# THEJAS32 register map
Vendor: CDAC; Series: VEGA; File version: 1.0
CDAC VEGA THEJAS32 RISC-V SoC
CPU: other r0p0, little endian, no MPU, no FPU, 0 interrupt priority bits
Registers are 32-bit, read-write, reset 0x0 unless marked. A register's access mark holds for its fields unless they carry their own. Offsets are from the block's base; lines under a group give offsets from that group; [hi:lo] are bit positions; {n}, {i} and the like mark numbered series; 'fields as' and 'values as' point back to an identical list; <NAME> marks a mode.

## Memory map
0x10000100 UART0 size 0x100 — UART channel 0
0x10000200 UART1 size 0x100 — UART channel 1
0x10000300 UART2 size 0x100 — UART channel 2
0x10000600 SPI0 size 0x100 — SPI controller 0
0x10000700 SPI1 size 0x100 — SPI controller 1
0x10000800 I2C0 size 0x100 — I2C controller 0
0x10000900 I2C1 size 0x100 — I2C controller 1
0x10000A00 TIMER0 size 0x100 — Timer channel 0
0x10000A00 TIMER_GLOBAL size 0x100 — Timer global interrupt status registers
0x10000A14 TIMER1 size 0x100 — Timer channel 1
0x10000A28 TIMER2 size 0x100 — Timer channel 2
0x10001000 I2C2 size 0x100 — I2C controller 2 - bus for the board's onboard ADS1015 ADC
0x10001000 ADC size 0x100 — 4-channel ADC
0x10080000 GPIO0 size 0x50000 — GPIO bank 0 (pins 0-15)
0x10180000 GPIO1 size 0x50000 — GPIO bank 1 (pins 16-31)
0x10200100 SPI2 size 0x100 — SPI controller 2
0x10200200 SPI3 size 0x100 — SPI controller 3
{0x10400000+0x10*n} PWM{n} size 0x100 (n=0..7) — PWM channel {n}
0x10400080 PWM_GLOBAL size 0x100 — PWM global control
0x20010000 PLIC size 0x800 — Platform-Level Interrupt Controller

## Interrupts
0 UART0
1 UART1
2 UART2
3 SPI0
4 SPI1
5 I2C0
6 I2C1
7 TIMER0
8 TIMER1
9 TIMER2
10 GPIO0
{n+10} GPIO{n} (GPIO0) (n=1..12)

## UART0 — UART channel 0
Base 0x10000100
Same registers: UART1 0x10000200, UART2 0x10000300
0x00 RBR ro — Receiver Buffer Register
  [7:0] DATA — Received data byte
0x00 THR wo (alternate view of RBR) — Transmit Holding Register
  [7:0] DATA — Transmit data byte
0x00 DLL (alternate view of RBR) — Divisor Latch Low Register
  [7:0] DATA — Divisor latch low byte when LCR.DLAB=1
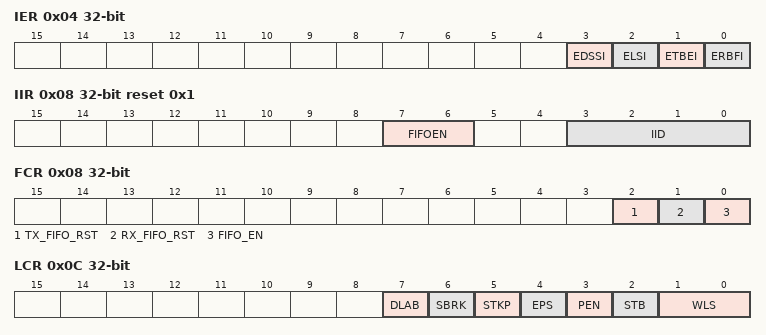
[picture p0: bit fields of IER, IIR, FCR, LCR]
0x04 IER — Interrupt Enable Register
  [3] EDSSI — Enable modem status interrupt
  [2] ELSI — Enable receiver line status interrupt
  [1] ETBEI — Enable transmitter holding register empty interrupt
  [0] ERBFI — Enable received data available interrupt
0x04 DLH (alternate view of IER) — Divisor Latch High Register
  [7:0] DATA — Divisor latch high byte when LCR.DLAB=1
0x08 IIR ro reset 0x1 — Interrupt Identification Register
  [7:6] FIFOEN — FIFO enable status
  [3:0] IID — Interrupt identification
0x08 FCR wo (alternate view of IIR) — FIFO Control Register
  [2] TX_FIFO_RST — Transmit FIFO reset
  [1] RX_FIFO_RST — Receive FIFO reset
  [0] FIFO_EN — FIFO enable
0x0C LCR — Line Control Register
  [7] DLAB — Divisor latch access bit
  [6] SBRK — Set break
  [5] STKP — Stick parity
  [4] EPS — Even parity select
  [3] PEN — Parity enable
  [2] STB — Number of stop bits
  [1:0] WLS — Word length select (0=5bit,1=6bit,2=7bit,3=8bit)
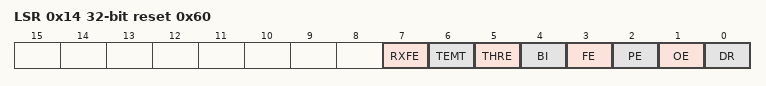
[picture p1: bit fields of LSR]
0x14 LSR ro reset 0x60 — Line Status Register
  [7] RXFE — Receiver FIFO error
  [6] TEMT — Transmitter empty
  [5] THRE — Transmitter holding register empty
  [4] BI — Break interrupt
  [3] FE — Framing error
  [2] PE — Parity error
  [1] OE — Overrun error
  [0] DR — Data ready

## SPI0 — SPI controller 0
Base 0x10000600
Same registers: SPI1 0x10000700, SPI2 0x10200100, SPI3 0x10200200
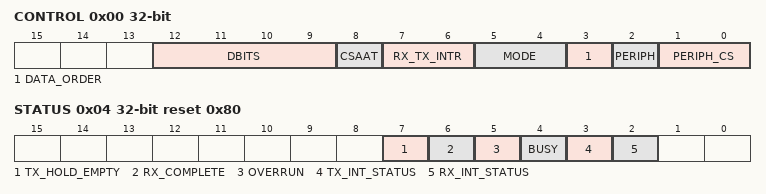
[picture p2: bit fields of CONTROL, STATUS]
0x00 CONTROL — SPI Control Register
  [12:9] DBITS — Data bits per transfer
  [8] CSAAT — Chip select active after transfer
  [7:6] RX_TX_INTR — RX/TX interrupt enable
  [5:4] MODE — SPI mode (clock polarity/phase)
  [3] DATA_ORDER — Data order (0=MSB first, 1=LSB first)
  [2] PERIPH — Peripheral type (0=fixed, 1=variable)
  [1:0] PERIPH_CS — Peripheral chip select
0x04 STATUS ro reset 0x80 — SPI Status Register
  [7] TX_HOLD_EMPTY — Transmit holding register empty
  [6] RX_COMPLETE — Receive complete
  [5] OVERRUN — Overrun error
  [4] BUSY — SPI busy
  [3] TX_INT_STATUS — TX interrupt status
  [2] RX_INT_STATUS — RX interrupt status
0x08 BAUDRATE reset 0x60 — SPI Baud Rate Divisor
0x0C TXDATA wo — SPI Transmit Data Register
  [15:0] DATA — Transmit data
0x10 RXDATA ro — SPI Receive Data Register
  [15:0] DATA — Received data

## I2C0 — I2C controller 0
Base 0x10000800
Same registers: I2C1 0x10000900, I2C2 0x10001000
0x00 CR 8-bit — Control Register
0x01 SR0 8-bit ro reset 0xD8 — Status Register 0
0x02 SR1 8-bit ro — Status Register 1
0x03 IER 8-bit — Interrupt Enable Register
0x04 TXFF 8-bit wo — Transmit FIFO
0x05 RXFF 8-bit ro — Receive FIFO
0x06 CHL 8-bit reset 0x7D — Clock Low Period
0x07 CHH 8-bit — Clock High Period
0x08 CHHL 8-bit reset 0x3E — Clock Low Period (extended)
0x09 CHHH 8-bit — Clock High Period (extended)
0x0A TXCLR 8-bit wo — TX Clear

## TIMER0 — Timer channel 0
Base 0x10000A00
Same registers: TIMER1 0x10000A14, TIMER2 0x10000A28
0x00 LOAD_COUNT — Timer load count value
0x04 CURRENT_VALUE ro — Timer current value
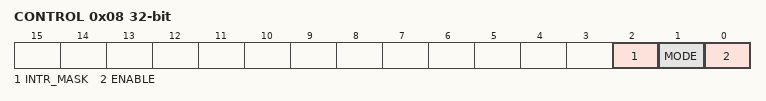
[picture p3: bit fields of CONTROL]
0x08 CONTROL — Timer control register
  [2] INTR_MASK — Interrupt mask (0=unmasked, 1=masked)
  [1] MODE — Timer mode (0=free-running, 1=user-defined)
  [0] ENABLE — Timer enable
0x0C EOI ro — Timer end-of-interrupt (read clears interrupt)
0x10 INTR_STATUS ro — Timer interrupt status

## TIMER_GLOBAL — Timer global interrupt status registers
Base 0x10000A00
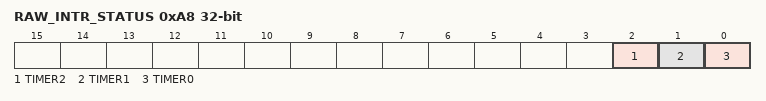
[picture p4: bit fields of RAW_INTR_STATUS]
0xA8 RAW_INTR_STATUS ro — Global raw timer interrupt status register
  [2] TIMER2 — Timer 2 raw interrupt status
  [1] TIMER1 — Timer 1 raw interrupt status
  [0] TIMER0 — Timer 0 raw interrupt status

## GPIO0 — GPIO bank 0 (pins 0-15)
Base 0x10080000
Same registers: GPIO1 0x10180000
0x00 DATA 16-bit — GPIO data register (bit-banded: access pin N via base + (1<<N)<<2)
  [15:0] PIN — Pin data value
0x3FFFC DATAOUT 16-bit — GPIO data register (all 16 pins, bulk read/write)
  [15:0] PINS — All pin values
0x40000 DIR 16-bit — GPIO direction register (0=input, 1=output)
  [15:0] PIN — Direction bits for pins 0-15

## ADC — 4-channel ADC
Base 0x10001000
0x00 ADDRESS — ADC channel select register
  [1:0] CHANNEL — ADC channel number (0-3)
0x04 STATUS ro — ADC status register
  [0] DONE — Conversion complete
0x08 DATA ro — ADC conversion data register
  [11:0] VALUE — ADC conversion result

## PWM0 — PWM channel 0
Base 0x10400000
Same registers: PWM1 0x10400010, PWM2 0x10400020, PWM3 0x10400030, PWM4 0x10400040, PWM5 0x10400050, PWM6 0x10400060, PWM7 0x10400070
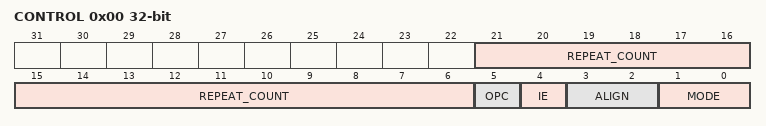
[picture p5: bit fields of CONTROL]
0x00 CONTROL — PWM channel control register
  [21:6] REPEAT_COUNT — Repeat count for one-shot mode
  [5] OPC — Output polarity control
  [4] IE — Interrupt enable
  [3:2] ALIGN — Alignment control (0=left, 1=right)
  [1:0] MODE — Mode (0=idle, 1=one-shot, 2=continuous)
0x04 STATUS ro — PWM channel status register
  [0] ACTIVE — Channel active
0x08 PERIOD — PWM period value
0x0C ON_OFF — PWM on/off time value

## PWM_GLOBAL — PWM global control
Base 0x10400080
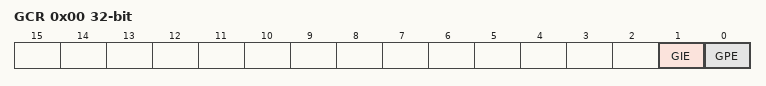
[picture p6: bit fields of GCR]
0x00 GCR — PWM Global Control Register
  [1] GIE — Global interrupt enable
  [0] GPE — Global PWM enable

## PLIC — Platform-Level Interrupt Controller
Base 0x20010000
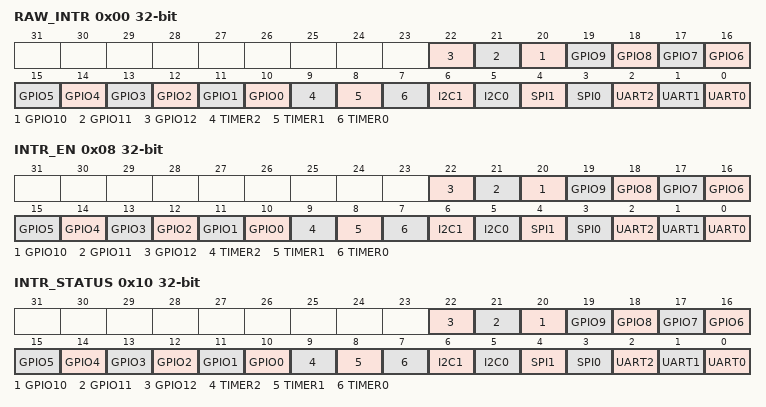
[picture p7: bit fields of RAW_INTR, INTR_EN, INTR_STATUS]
0x00 RAW_INTR ro — Raw interrupt status
  [n+10] GPIO{n} (n=0..12) — GPIO{n} interrupt
  [9] TIMER2 — TIMER2 interrupt
  [8] TIMER1 — TIMER1 interrupt
  [7] TIMER0 — TIMER0 interrupt
  [6] I2C1 — I2C1 interrupt
  [5] I2C0 — I2C0 interrupt
  [4] SPI1 — SPI1 interrupt
  [3] SPI0 — SPI0 interrupt
  [2] UART2 — UART2 interrupt
  [1] UART1 — UART1 interrupt
  [0] UART0 — UART0 interrupt
0x08 INTR_EN — Interrupt enable register
  fields as RAW_INTR
0x10 INTR_STATUS ro — Masked interrupt status
  fields as RAW_INTR
0x400 SW_INTR_EN — Software interrupt enable

## Licence text in the file
MIT License
